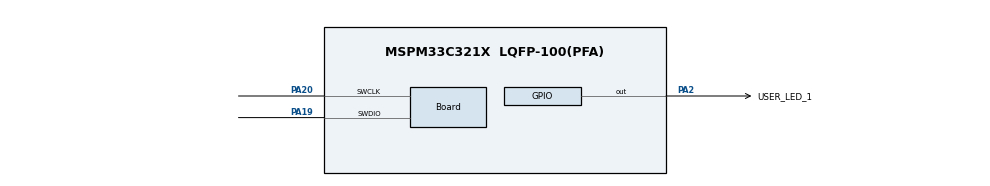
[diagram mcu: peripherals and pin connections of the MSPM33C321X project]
/**
 * @cliArgs --device "MSPM33C321X" --part "Default" --package "LQFP-100(PFA)" --product "mspm33_sdk@1.00.00.00"
 * @versions {"tool":"1.25.0+4268"}
 */

/**
 * Import the modules used in this configuration.
 */
const GPIO  = scripting.addModule("/ti/driverlib/GPIO", {}, false);
const GPIO1 = GPIO.addInstance();

/**
 * Write custom configuration values to the imported modules.
 */
GPIO1.$name                               = "GPIO_LEDS";
GPIO1.associatedPins[0].$name             = "USER_LED_1";
GPIO1.associatedPins[0].launchPadShortcut = "LED2BlueEn";
GPIO1.associatedPins[0].pin.$assign       = "PA2";

const Board                       = scripting.addModule("/ti/driverlib/Board", {}, false);
Board.peripheral.$assign          = "DEBUGSS";
Board.peripheral.swclkPin.$assign = "PA20";
Board.peripheral.swdioPin.$assign = "PA19";

const SYSCTL              = scripting.addModule("/ti/driverlib/SYSCTL", {}, false);
SYSCTL.peripheral.$assign = "SYSCTL";

const ProjectConfig              = scripting.addModule("/ti/project_config/ProjectConfig", {}, false);
ProjectConfig.migrationCondition = true;
